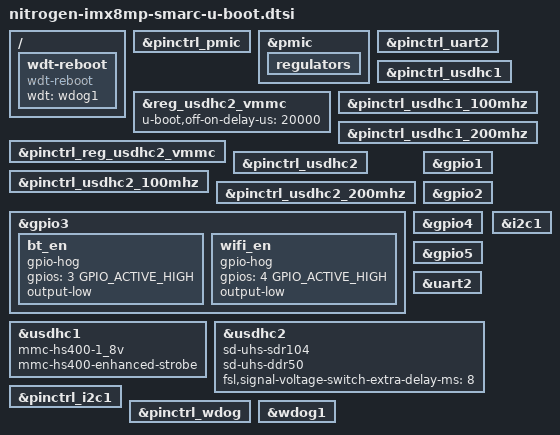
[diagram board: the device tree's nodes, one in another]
// SPDX-License-Identifier: GPL-2.0+
/*
 * Copyright 2025 Ezurio LLC
 */

#include "imx8mp-u-boot.dtsi"

/ {
	wdt-reboot {
		compatible = "wdt-reboot";
		wdt = <&wdog1>;
		bootph-pre-ram;
	};
};

&pinctrl_pmic {
	bootph-pre-ram;
};

&pmic {
	bootph-pre-ram;

	regulators {
		bootph-pre-ram;
	};
};

&reg_usdhc2_vmmc {
	u-boot,off-on-delay-us = <20000>;
};

&pinctrl_reg_usdhc2_vmmc {
	bootph-pre-ram;
};

&pinctrl_uart2 {
	bootph-pre-ram;
};

&pinctrl_usdhc1 {
	bootph-pre-ram;
};

&pinctrl_usdhc1_100mhz {
	bootph-pre-ram;
};

&pinctrl_usdhc1_200mhz {
	bootph-pre-ram;
};

&pinctrl_usdhc2 {
	bootph-pre-ram;
};

&pinctrl_usdhc2_100mhz {
	bootph-pre-ram;
};

&pinctrl_usdhc2_200mhz {
	bootph-pre-ram;
};

&gpio1 {
	bootph-pre-ram;
};

&gpio2 {
	bootph-pre-ram;
};

&gpio3 {
	bootph-pre-ram;

	bt_en {
		bootph-pre-ram;
		gpio-hog;
		gpios = <3 GPIO_ACTIVE_HIGH>;
		output-low;
	};

	wifi_en {
		bootph-pre-ram;
		gpio-hog;
		gpios = <4 GPIO_ACTIVE_HIGH>;
		output-low;
	};
};

&gpio4 {
	bootph-pre-ram;
};

&gpio5 {
	bootph-pre-ram;
};

&uart2 {
	bootph-pre-ram;
};

&usdhc1 {
	bootph-pre-ram;
	mmc-hs400-1_8v;
	mmc-hs400-enhanced-strobe;
};

&usdhc2 {
	bootph-pre-ram;
	sd-uhs-sdr104;
	sd-uhs-ddr50;
	fsl,signal-voltage-switch-extra-delay-ms = <8>;
};

&i2c1 {
	bootph-pre-ram;
};

&pinctrl_i2c1 {
	bootph-pre-ram;
};

&pinctrl_wdog {
	bootph-pre-ram;
};

&wdog1 {
	bootph-pre-ram;
};
